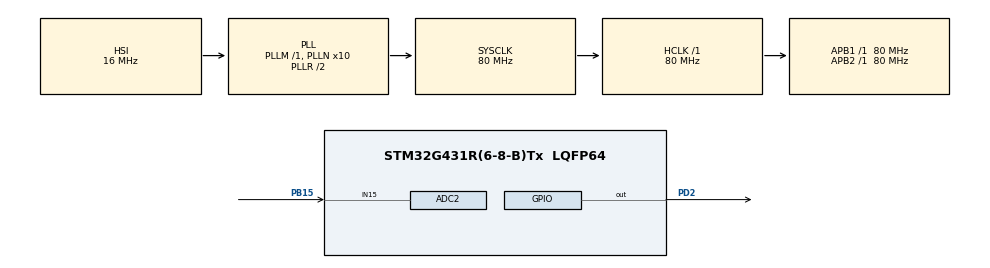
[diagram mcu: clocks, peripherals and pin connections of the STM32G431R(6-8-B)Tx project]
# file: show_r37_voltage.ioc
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ADC2.Channel-0\#ChannelRegularConversion=ADC_CHANNEL_15
ADC2.NbrOfConversionFlag=1
ADC2.OffsetNumber-0\#ChannelRegularConversion=ADC_OFFSET_NONE
ADC2.Rank-0\#ChannelRegularConversion=1
ADC2.SamplingTime-0\#ChannelRegularConversion=ADC_SAMPLETIME_2CYCLES_5
Mcu.Family=STM32G4
Mcu.Name=STM32G431R(6-8-B)Tx
Mcu.Package=LQFP64
NVIC.PriorityGroup=NVIC_PRIORITYGROUP_4
PA13.Mode=Serial_Wire
PA13.Signal=SYS_JTMS-SWDIO
PA14.Mode=Serial_Wire
PA14.Signal=SYS_JTCK-SWCLK
PB15.Mode=IN15-Single-Ended
PB15.Signal=ADC2_IN15
PD2.Signal=GPIO_Output
ProjectManager.HeapSize=0x200
ProjectManager.StackSize=0x400
ProjectManager.TargetToolchain=MDK-ARM V5.32
RCC.ADC12Freq_Value=80000000
RCC.AHBFreq_Value=80000000
RCC.APB1Freq_Value=80000000
RCC.APB1TimFreq_Value=80000000
RCC.APB2Freq_Value=80000000
RCC.APB2TimFreq_Value=80000000
RCC.CortexFreq_Value=80000000
RCC.EXTERNAL_CLOCK_VALUE=12288000
RCC.HCLKFreq_Value=80000000
RCC.HSE_VALUE=8000000
RCC.HSI48_VALUE=48000000
RCC.HSI_VALUE=16000000
RCC.LSE_VALUE=32768
RCC.PLLN=10
RCC.SYSCLKFreq_VALUE=80000000
RCC.SYSCLKSource=RCC_SYSCLKSOURCE_PLLCLK
RCC.USBFreq_Value=80000000
RCC.VCOOutputFreq_Value=160000000
VP_SYS_VS_DBSignals.Mode=DisableDeadBatterySignals
board=custom

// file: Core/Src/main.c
/* USER CODE BEGIN Header */
/**
  ******************************************************************************
  * @file           : main.c
  * @brief          : Main program body
  ******************************************************************************
  * @attention
  *
  * <h2><center>&copy; Copyright (c) 2025 STMicroelectronics.
  * All rights reserved.</center></h2>
  *
  * This software component is licensed by ST under BSD 3-Clause license,
  * the "License"; You may not use this file except in compliance with the
  * License. You may obtain a copy of the License at:
  *                        opensource.org/licenses/BSD-3-Clause
  *
  ******************************************************************************
  */
/* USER CODE END Header */
#include "main.h"
#include "adc.h"
#include "gpio.h"

/* USER CODE BEGIN Includes */
#include "lcd.h"
#include <stdio.h>
/* USER CODE END Includes */

void SystemClock_Config(void);
static void init_lcd()
{
    LCD_Init();
    LCD_Clear(Black);
    LCD_SetBackColor(Black);
    LCD_SetTextColor(White);
}
/* USER CODE BEGIN 0 */
char buffer[20];

static double get_adc_value()
{
    HAL_ADC_Start(&hadc2);
    uint32_t result = HAL_ADC_GetValue(&hadc2);
    return (double)result * (3.3) / 4096;
}

static void display_lcd()
{
    snprintf(buffer, 20, "        DATA");
    LCD_DisplayStringLine(Line3, (u8*)buffer);
    double voltage = get_adc_value();
    snprintf(buffer, 20, "     VR37:%.2fV", voltage);
    LCD_DisplayStringLine(Line4, (u8*)buffer);

}

/* USER CODE END 0 */

int main(void)
{

  /* MCU Configuration--------------------------------------------------------*/

  /* Reset of all peripherals, Initializes the Flash interface and the Systick. */
  HAL_Init();

  /* Configure the system clock */
  SystemClock_Config();

  /* Initialize all configured peripherals */
  MX_GPIO_Init();
  MX_ADC2_Init();
  /* USER CODE BEGIN 2 */
    init_led();
    init_lcd();

  /* USER CODE END 2 */

  /* Infinite loop */
  while (1)
  {

    /* USER CODE BEGIN 3 */
      display_lcd();
      HAL_Delay(300);
  }
  /* USER CODE END 3 */
}

void SystemClock_Config(void)
{
  RCC_OscInitTypeDef RCC_OscInitStruct = {0};
  RCC_ClkInitTypeDef RCC_ClkInitStruct = {0};
  RCC_PeriphCLKInitTypeDef PeriphClkInit = {0};

  /** Configure the main internal regulator output voltage
  */
  HAL_PWREx_ControlVoltageScaling(PWR_REGULATOR_VOLTAGE_SCALE1);
  /** Initializes the RCC Oscillators according to the specified parameters
  * in the RCC_OscInitTypeDef structure.
  */
  RCC_OscInitStruct.OscillatorType = RCC_OSCILLATORTYPE_HSI;
  RCC_OscInitStruct.HSIState = RCC_HSI_ON;
  RCC_OscInitStruct.HSICalibrationValue = RCC_HSICALIBRATION_DEFAULT;
  RCC_OscInitStruct.PLL.PLLState = RCC_PLL_ON;
  RCC_OscInitStruct.PLL.PLLSource = RCC_PLLSOURCE_HSI;
  RCC_OscInitStruct.PLL.PLLM = RCC_PLLM_DIV1;
  RCC_OscInitStruct.PLL.PLLN = 10;
  RCC_OscInitStruct.PLL.PLLP = RCC_PLLP_DIV2;
  RCC_OscInitStruct.PLL.PLLQ = RCC_PLLQ_DIV2;
  RCC_OscInitStruct.PLL.PLLR = RCC_PLLR_DIV2;
  if (HAL_RCC_OscConfig(&RCC_OscInitStruct) != HAL_OK)
  {
    Error_Handler();
  }
  /** Initializes the CPU, AHB and APB buses clocks
  */
  RCC_ClkInitStruct.ClockType = RCC_CLOCKTYPE_HCLK|RCC_CLOCKTYPE_SYSCLK
                              |RCC_CLOCKTYPE_PCLK1|RCC_CLOCKTYPE_PCLK2;
  RCC_ClkInitStruct.SYSCLKSource = RCC_SYSCLKSOURCE_PLLCLK;
  RCC_ClkInitStruct.AHBCLKDivider = RCC_SYSCLK_DIV1;
  RCC_ClkInitStruct.APB1CLKDivider = RCC_HCLK_DIV1;
  RCC_ClkInitStruct.APB2CLKDivider = RCC_HCLK_DIV1;

  if (HAL_RCC_ClockConfig(&RCC_ClkInitStruct, FLASH_LATENCY_2) != HAL_OK)
  {
    Error_Handler();
  }
  /** Initializes the peripherals clocks
  */
  PeriphClkInit.PeriphClockSelection = RCC_PERIPHCLK_ADC12;
  PeriphClkInit.Adc12ClockSelection = RCC_ADC12CLKSOURCE_SYSCLK;
  if (HAL_RCCEx_PeriphCLKConfig(&PeriphClkInit) != HAL_OK)
  {
    Error_Handler();
  }
}

void Error_Handler(void)
{
  __disable_irq();
  while (1)
  {
  }
}

/************************ (C) COPYRIGHT STMicroelectronics *****END OF FILE****/
